AUTOSAR XML (schema 4-2-2)
package /COM_SWC
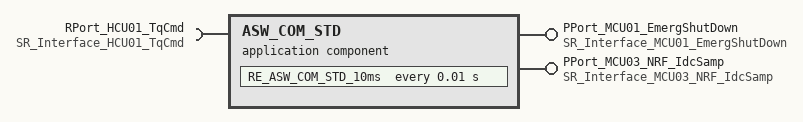
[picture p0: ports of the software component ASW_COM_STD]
  application sw component type ASW_COM_STD
    provide port PPort_MCU01_EmergShutDown: provided-interface=SR_Interface_MCU01_EmergShutDown
    provide port PPort_MCU03_NRF_IdcSamp: provided-interface=SR_Interface_MCU03_NRF_IdcSamp
    require port RPort_HCU01_TqCmd: nonqueued-receiver-com-spec{alive-timeout=0.3, data-element=HCU01_TqCmd}, required-interface=SR_Interface_HCU01_TqCmd
    behavior IB_ASW_COM_STD
      timing event TE_10ms_RE_ASW_COM_STD: start-on-event=RE_ASW_COM_STD_10ms, period=0.01
      runnable RE_ASW_COM_STD_10ms
        data-receive-point-by-arguments:
          access RP_HCU01_TqCmd: accessed-variable=RPort_HCU01_TqCmd.HCU01_TqCmd
        data-send-points:
          access SP_MCU01_EmergShutDown: accessed-variable=PPort_MCU01_EmergShutDown.MCU01_EmergShutDown
          access SP_MCU03_NRF_IdcSamp: accessed-variable=PPort_MCU03_NRF_IdcSamp.MCU03_NRF_IdcSamp
